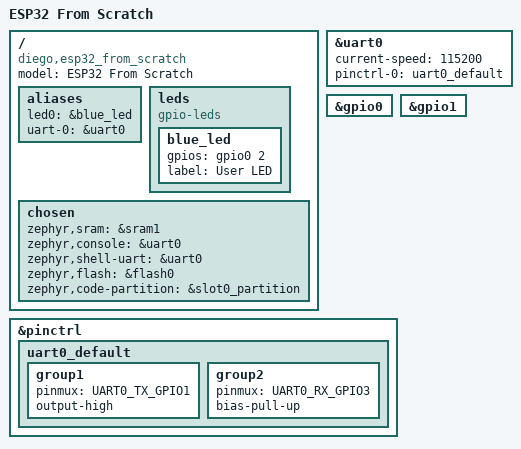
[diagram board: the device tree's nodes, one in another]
/dts-v1/;

#include <espressif/esp32/esp32_wroom_32ue_n4.dtsi>
#include <zephyr/dt-bindings/input/input-event-codes.h>
#include <espressif/partitions_0x1000_amp.dtsi>
#include <zephyr/dt-bindings/pinctrl/esp-pinctrl-common.h>
#include <zephyr/dt-bindings/pinctrl/esp32-pinctrl.h>
#include <zephyr/dt-bindings/pinctrl/esp32-gpio-sigmap.h>


/ {
	model = "ESP32 From Scratch";
	compatible = "diego,esp32_from_scratch";

	aliases {
		led0 = &blue_led;
		uart-0 = &uart0;
	};

	leds {
		compatible = "gpio-leds";

		blue_led: blue_led {
			gpios = <&gpio0 2 GPIO_ACTIVE_HIGH>;
			label = "User LED";
		};
	};

	chosen {
		zephyr,sram = &sram1;
		zephyr,console = &uart0;
		zephyr,shell-uart = &uart0;
		zephyr,flash = &flash0;
		zephyr,code-partition = &slot0_partition;
	};
};

&uart0 {
	status = "okay";
	current-speed = <115200>;
	pinctrl-0 = <&uart0_default>;
	pinctrl-names = "default";
};

&gpio0 {
	status = "okay";
};

&gpio1 {
	status = "okay";
};

&pinctrl {
	uart0_default: uart0_default {
		group1 {
			pinmux = <UART0_TX_GPIO1>;
			output-high;
		};

		group2 {
			pinmux = <UART0_RX_GPIO3>;
			bias-pull-up;
		};
	};
};
